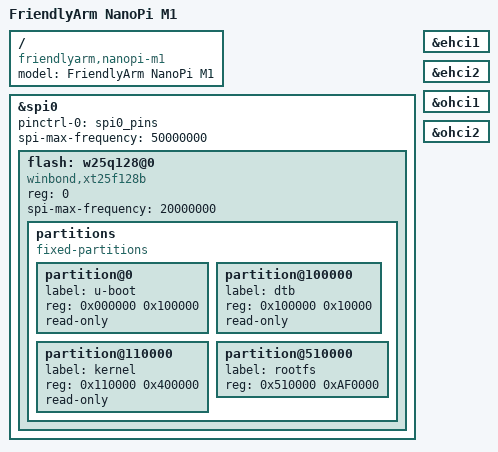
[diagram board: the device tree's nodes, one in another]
/*
 * Copyright (C) 2016 Milo Kim <woogyom.kim@gmail.com>
 *
 * This file is dual-licensed: you can use it either under the terms
 * of the GPL or the X11 license, at your option. Note that this dual
 * licensing only applies to this file, and not this project as a
 * whole.
 *
 *  a) This file is free software; you can redistribute it and/or
 *     modify it under the terms of the GNU General Public License as
 *     published by the Free Software Foundation; either version 2 of the
 *     License, or (at your option) any later version.
 *
 *     This file is distributed in the hope that it will be useful,
 *     but WITHOUT ANY WARRANTY; without even the implied warranty of
 *     MERCHANTABILITY or FITNESS FOR A PARTICULAR PURPOSE.  See the
 *     GNU General Public License for more details.
 *
 * Or, alternatively,
 *
 *  b) Permission is hereby granted, free of charge, to any person
 *     obtaining a copy of this software and associated documentation
 *     files (the "Software"), to deal in the Software without
 *     restriction, including without limitation the rights to use,
 *     copy, modify, merge, publish, distribute, sublicense, and/or
 *     sell copies of the Software, and to permit persons to whom the
 *     Software is furnished to do so, subject to the following
 *     conditions:
 *
 *     The above copyright notice and this permission notice shall be
 *     included in all copies or substantial portions of the Software.
 *
 *     THE SOFTWARE IS PROVIDED "AS IS", WITHOUT WARRANTY OF ANY KIND,
 *     EXPRESS OR IMPLIED, INCLUDING BUT NOT LIMITED TO THE WARRANTIES
 *     OF MERCHANTABILITY, FITNESS FOR A PARTICULAR PURPOSE AND
 *     NONINFRINGEMENT. IN NO EVENT SHALL THE AUTHORS OR COPYRIGHT
 *     HOLDERS BE LIABLE FOR ANY CLAIM, DAMAGES OR OTHER LIABILITY,
 *     WHETHER IN AN ACTION OF CONTRACT, TORT OR OTHERWISE, ARISING
 *     FROM, OUT OF OR IN CONNECTION WITH THE SOFTWARE OR THE USE OR
 *     OTHER DEALINGS IN THE SOFTWARE.
 */

#include "sun8i-h3-nanopi.dtsi"

/ {
	model = "FriendlyArm NanoPi M1";
	compatible = "friendlyarm,nanopi-m1", "allwinner,sun8i-h3";
};

&spi0 {
    pinctrl-names = "default";
    pinctrl-0 = <&spi0_pins>;
    status = "okay";
    spi-max-frequency = <50000000>;
    flash: w25q128@0 {
        #address-cells = <1>;
        #size-cells = <1>;
        //compatible = "winbond,w25q128", "jedec,spi-nor";
        compatible = "winbond,xt25f128b", "jedec,spi-nor";
        reg = <0>;
        spi-max-frequency = <20000000>;
        partitions {
            compatible = "fixed-partitions";
            #address-cells = <1>;
            #size-cells = <1>;

            partition@0 {
                label = "u-boot";
                reg = <0x000000 0x100000>;
                read-only;
            };

            partition@100000 {
                label = "dtb";
                reg = <0x100000 0x10000>;
                read-only;
            };

            partition@110000 {
                label = "kernel";
                reg = <0x110000 0x400000>;
                read-only;
            };

            partition@510000 {
                label = "rootfs";
                reg = <0x510000 0xAF0000>;
            };
        };
    };
};

&ehci1 {
	status = "okay";
};

&ehci2 {
	status = "okay";
};

&ohci1 {
	status = "okay";
};

&ohci2 {
	status = "okay";
};
